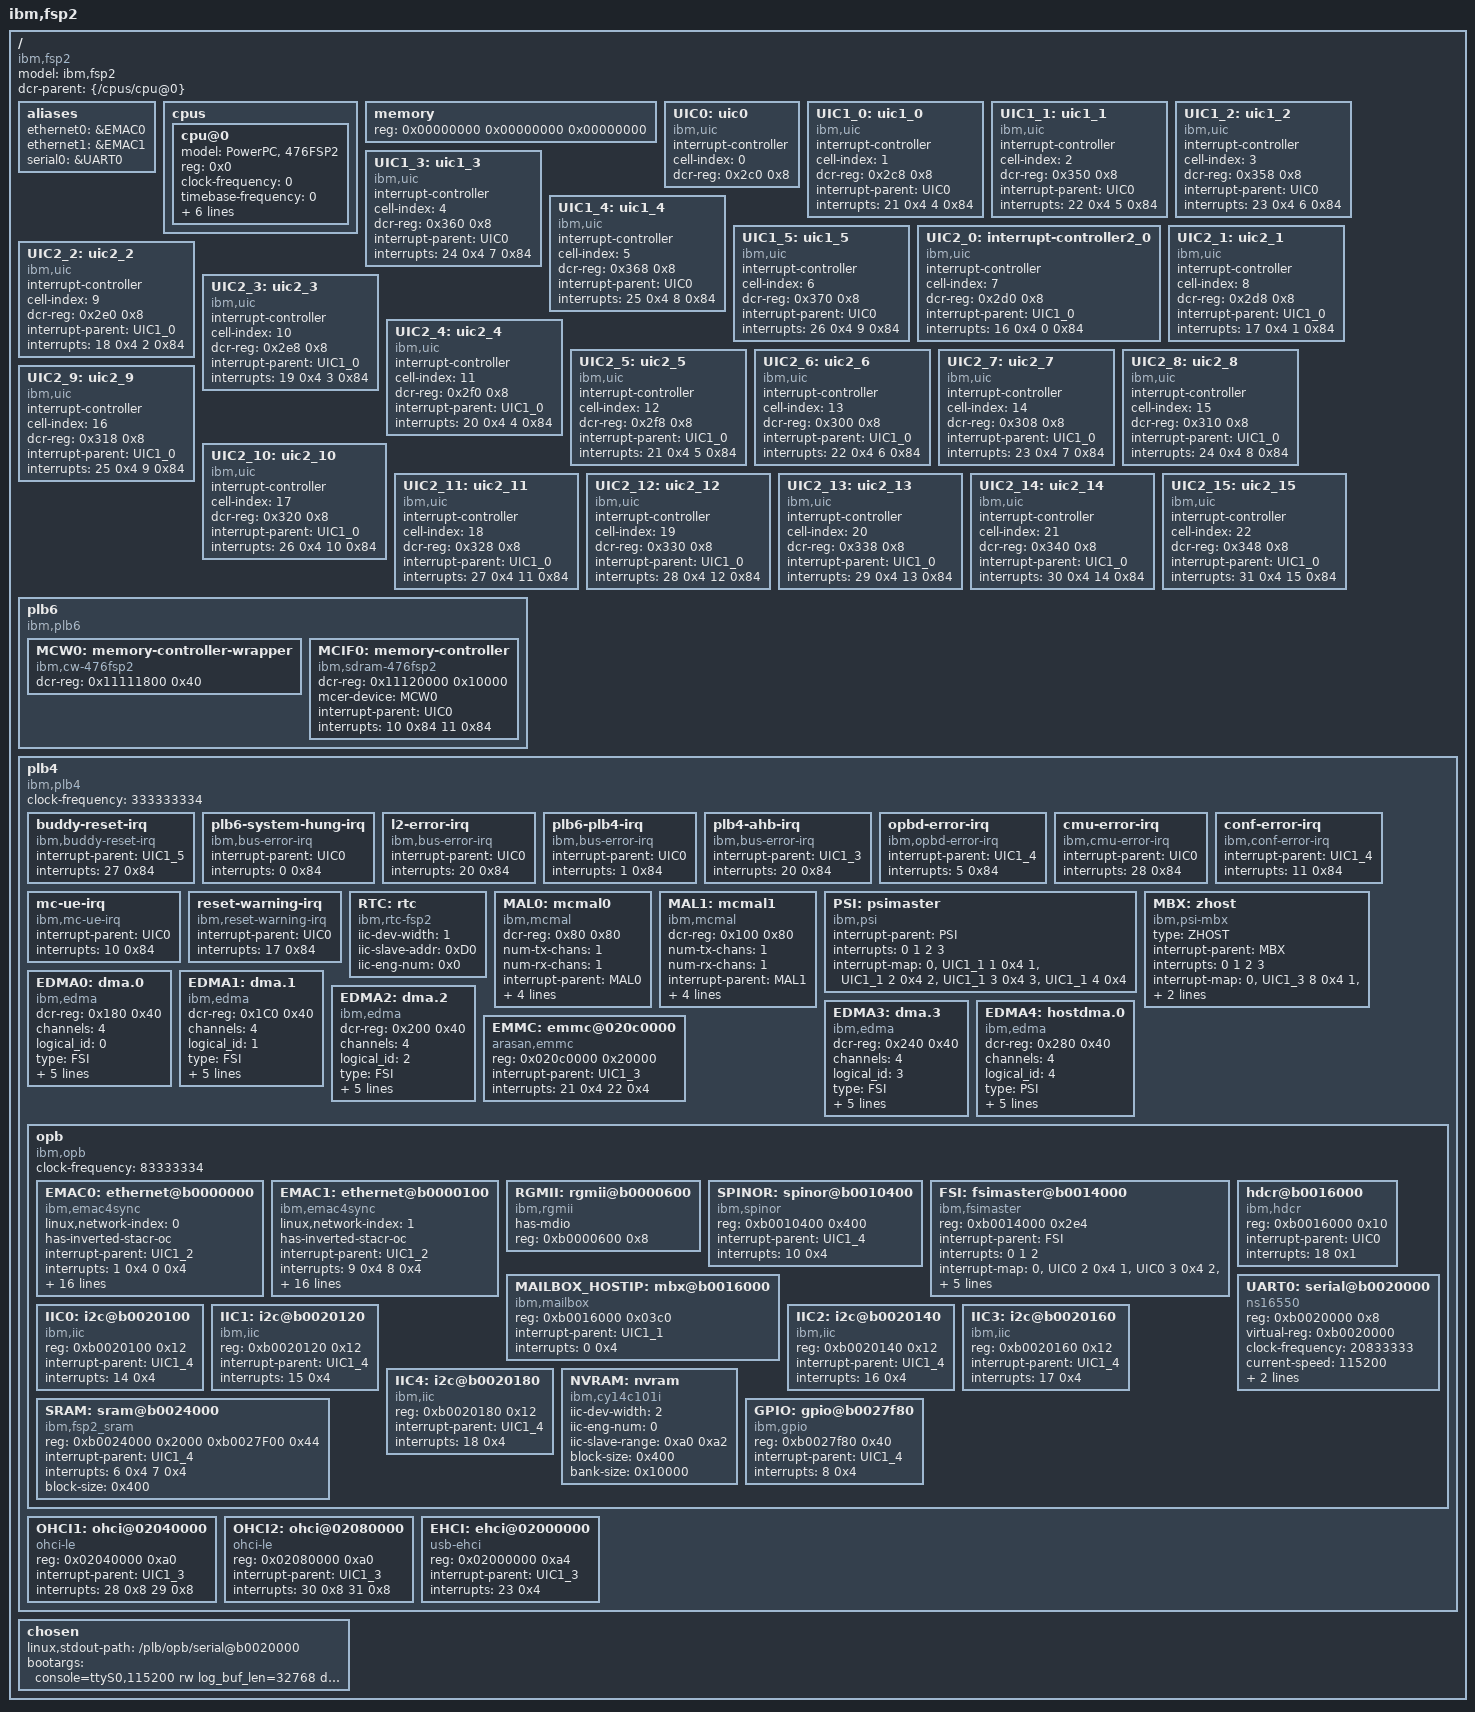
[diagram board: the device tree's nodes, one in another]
/*
 *   Copyright (c) International Business Machines Corp., 2010, 2012
 *
 *   This program is free software;  you can redistribute it and/or modify
 *   it under the terms of the GNU General Public License as published by
 *   the Free Software Foundation; either version 2 of the License, or
 *   (at your option) any later version.
 *
 *   This program is distributed in the hope that it will be useful,
 *   but WITHOUT ANY WARRANTY;  without even the implied warranty of
 *   MERCHANTABILITY or FITNESS FOR A PARTICULAR PURPOSE.  See
 *   the GNU General Public License for more details.
 *
 *   You should have received a copy of the GNU General Public License
 *   along with this program;  if not, write to the Free Software
 *   Foundation, Inc., 59 Temple Place, Suite 330, Boston, MA 02111-1307 USA
 */

/dts-v1/;

/ {
	#address-cells = <2>;
	#size-cells = <1>;
	model = "ibm,fsp2";
	compatible = "ibm,fsp2";
	dcr-parent = <&{/cpus/cpu@0}>;

	aliases {
		ethernet0 = &EMAC0;
		ethernet1 = &EMAC1;
		serial0 = &UART0;
	};

	cpus {
		#address-cells = <1>;
		#size-cells = <0>;

		cpu@0 {
			device_type = "cpu";
			model = "PowerPC, 476FSP2";
			reg = <0x0>;
			clock-frequency = <0>;    /* Filled in by cuboot */
			timebase-frequency = <0>; /* Filled in by cuboot */
			i-cache-line-size = <32>;
			d-cache-line-size = <32>;
			d-cache-size = <32768>;
			i-cache-size = <32768>;
			dcr-controller;
			dcr-access-method = "native";
		};
	};

	memory {
		device_type = "memory";
		reg = <0x00000000 0x00000000 0x00000000>; /* Filled in by
							     cuboot */
	};

	UIC0: uic0 {
		#address-cells = <0>;
		#size-cells = <0>;
		#interrupt-cells = <2>;
		compatible = "ibm,uic";
		interrupt-controller;
		cell-index = <0>;
		dcr-reg = <0x2c0 0x8>;
	};

	/* "interrupts" field is <bit level bit level>
	   first pair is non-critical, second is critical */
	UIC1_0: uic1_0 {
		#address-cells = <0>;
		#size-cells = <0>;
		#interrupt-cells = <2>;
		compatible = "ibm,uic";
		interrupt-controller;
		cell-index = <1>;
		dcr-reg = <0x2c8 0x8>;
		interrupt-parent = <&UIC0>;
		interrupts = <21 0x4 4 0x84>;
	};

	/* PSI and DMA */
	UIC1_1: uic1_1 {
		#address-cells = <0>;
		#size-cells = <0>;
		#interrupt-cells = <2>;
		compatible = "ibm,uic";
		interrupt-controller;
		cell-index = <2>;
		dcr-reg = <0x350 0x8>;
		interrupt-parent = <&UIC0>;
		interrupts = <22 0x4 5 0x84>;
	};

	/* Ethernet and USB */
	UIC1_2: uic1_2 {
		#address-cells = <0>;
		#size-cells = <0>;
		#interrupt-cells = <2>;
		compatible = "ibm,uic";
		interrupt-controller;
		cell-index = <3>;
		dcr-reg = <0x358 0x8>;
		interrupt-parent = <&UIC0>;
		interrupts = <23 0x4 6 0x84>;
	};

	/* PLB Errors */
	UIC1_3: uic1_3 {
		#address-cells = <0>;
		#size-cells = <0>;
		#interrupt-cells = <2>;
		compatible = "ibm,uic";
		interrupt-controller;
		cell-index = <4>;
		dcr-reg = <0x360 0x8>;
		interrupt-parent = <&UIC0>;
		interrupts = <24 0x4 7 0x84>;
	};

	UIC1_4: uic1_4 {
		#address-cells = <0>;
		#size-cells = <0>;
		#interrupt-cells = <2>;
		compatible = "ibm,uic";
		interrupt-controller;
		cell-index = <5>;
		dcr-reg = <0x368 0x8>;
		interrupt-parent = <&UIC0>;
		interrupts = <25 0x4 8 0x84>;
	};

	UIC1_5: uic1_5 {
		#address-cells = <0>;
		#size-cells = <0>;
		#interrupt-cells = <2>;
		compatible = "ibm,uic";
		interrupt-controller;
		cell-index = <6>;
		dcr-reg = <0x370 0x8>;
		interrupt-parent = <&UIC0>;
		interrupts = <26 0x4 9 0x84>;
	};

	/* 2nd level UICs for FSI */
	UIC2_0: interrupt-controller2_0 {
		#address-cells = <0>;
		#size-cells = <0>;
		#interrupt-cells = <2>;
		compatible = "ibm,uic";
		interrupt-controller;
		cell-index = <7>;
		dcr-reg = <0x2d0 0x8>;
		interrupt-parent = <&UIC1_0>;
		interrupts = <16 0x4 0 0x84>;
	};

	UIC2_1: uic2_1 {
		#address-cells = <0>;
		#size-cells = <0>;
		#interrupt-cells = <2>;
		compatible = "ibm,uic";
		interrupt-controller;
		cell-index = <8>;
		dcr-reg = <0x2d8 0x8>;
		interrupt-parent = <&UIC1_0>;
		interrupts = <17 0x4 1 0x84>;
	};

	UIC2_2: uic2_2 {
		#address-cells = <0>;
		#size-cells = <0>;
		#interrupt-cells = <2>;
		compatible = "ibm,uic";
		interrupt-controller;
		cell-index = <9>;
		dcr-reg = <0x2e0 0x8>;
		interrupt-parent = <&UIC1_0>;
		interrupts = <18 0x4 2 0x84>;
	};

	UIC2_3: uic2_3 {
		#address-cells = <0>;
		#size-cells = <0>;
		#interrupt-cells = <2>;
		compatible = "ibm,uic";
		interrupt-controller;
		cell-index = <10>;
		dcr-reg = <0x2e8 0x8>;
		interrupt-parent = <&UIC1_0>;
		interrupts = <19 0x4 3 0x84>;
	};

	UIC2_4: uic2_4 {
		#address-cells = <0>;
		#size-cells = <0>;
		#interrupt-cells = <2>;
		compatible = "ibm,uic";
		interrupt-controller;
		cell-index = <11>;
		dcr-reg = <0x2f0 0x8>;
		interrupt-parent = <&UIC1_0>;
		interrupts = <20 0x4 4 0x84>;
	};

	UIC2_5: uic2_5 {
		#address-cells = <0>;
		#size-cells = <0>;
		#interrupt-cells = <2>;
		compatible = "ibm,uic";
		interrupt-controller;
		cell-index = <12>;
		dcr-reg = <0x2f8 0x8>;
		interrupt-parent = <&UIC1_0>;
		interrupts = <21 0x4 5 0x84>;
	};

	UIC2_6: uic2_6 {
		#address-cells = <0>;
		#size-cells = <0>;
		#interrupt-cells = <2>;
		compatible = "ibm,uic";
		interrupt-controller;
		cell-index = <13>;
		dcr-reg = <0x300 0x8>;
		interrupt-parent = <&UIC1_0>;
		interrupts = <22 0x4 6 0x84>;
	};

	UIC2_7: uic2_7 {
		#address-cells = <0>;
		#size-cells = <0>;
		#interrupt-cells = <2>;
		compatible = "ibm,uic";
		interrupt-controller;
		cell-index = <14>;
		dcr-reg = <0x308 0x8>;
		interrupt-parent = <&UIC1_0>;
		interrupts = <23 0x4 7 0x84>;
	};

	UIC2_8: uic2_8 {
		#address-cells = <0>;
		#size-cells = <0>;
		#interrupt-cells = <2>;
		compatible = "ibm,uic";
		interrupt-controller;
		cell-index = <15>;
		dcr-reg = <0x310 0x8>;
		interrupt-parent = <&UIC1_0>;
		interrupts = <24 0x4 8 0x84>;
	};

	UIC2_9: uic2_9 {
		#address-cells = <0>;
		#size-cells = <0>;
		#interrupt-cells = <2>;
		compatible = "ibm,uic";
		interrupt-controller;
		cell-index = <16>;
		dcr-reg = <0x318 0x8>;
		interrupt-parent = <&UIC1_0>;
		interrupts = <25 0x4 9 0x84>;
	};

	UIC2_10: uic2_10 {
		#address-cells = <0>;
		#size-cells = <0>;
		#interrupt-cells = <2>;
		compatible = "ibm,uic";
		interrupt-controller;
		cell-index = <17>;
		dcr-reg = <0x320 0x8>;
		interrupt-parent = <&UIC1_0>;
		interrupts = <26 0x4 10 0x84>;
	};

	UIC2_11: uic2_11 {
		#address-cells = <0>;
		#size-cells = <0>;
		#interrupt-cells = <2>;
		compatible = "ibm,uic";
		interrupt-controller;
		cell-index = <18>;
		dcr-reg = <0x328 0x8>;
		interrupt-parent = <&UIC1_0>;
		interrupts = <27 0x4 11 0x84>;
	};

	UIC2_12: uic2_12 {
		#address-cells = <0>;
		#size-cells = <0>;
		#interrupt-cells = <2>;
		compatible = "ibm,uic";
		interrupt-controller;
		cell-index = <19>;
		dcr-reg = <0x330 0x8>;
		interrupt-parent = <&UIC1_0>;
		interrupts = <28 0x4 12 0x84>;
	};

	UIC2_13: uic2_13 {
		#address-cells = <0>;
		#size-cells = <0>;
		#interrupt-cells = <2>;
		compatible = "ibm,uic";
		interrupt-controller;
		cell-index = <20>;
		dcr-reg = <0x338 0x8>;
		interrupt-parent = <&UIC1_0>;
		interrupts = <29 0x4 13 0x84>;
	};

	UIC2_14: uic2_14 {
		#address-cells = <0>;
		#size-cells = <0>;
		#interrupt-cells = <2>;
		compatible = "ibm,uic";
		interrupt-controller;
		cell-index = <21>;
		dcr-reg = <0x340 0x8>;
		interrupt-parent = <&UIC1_0>;
		interrupts = <30 0x4 14 0x84>;
	};

	UIC2_15: uic2_15 {
		#address-cells = <0>;
		#size-cells = <0>;
		#interrupt-cells = <2>;
		compatible = "ibm,uic";
		interrupt-controller;
		cell-index = <22>;
		dcr-reg = <0x348 0x8>;
		interrupt-parent = <&UIC1_0>;
		interrupts = <31 0x4 15 0x84>;
	};

	plb6 {
		compatible = "ibm,plb6";
		#address-cells = <2>;
		#size-cells = <1>;
		ranges;

		MCW0: memory-controller-wrapper {
			compatible = "ibm,cw-476fsp2";
			dcr-reg = <0x11111800 0x40>;
		};

		MCIF0: memory-controller {
			compatible = "ibm,sdram-476fsp2", "ibm,sdram-4xx-ddr3";
			dcr-reg = <0x11120000 0x10000>;
			mcer-device = <&MCW0>;
			interrupt-parent = <&UIC0>;
			interrupts = <10 0x84   /* ECC UE */
			              11 0x84>; /* ECC CE */
		};
	};

	plb4 {
		compatible = "ibm,plb4";
		#address-cells = <1>;
		#size-cells = <1>;
		ranges = <0x00000000 0x00000010 0x00000000 0x80000000
			  0x80000000 0x00000010 0x80000000 0x80000000>;
		clock-frequency = <333333334>;

		buddy-reset-irq {
			compatible = "ibm,buddy-reset-irq";

			#interrupt-cells = <2>;
			interrupt-parent = <&UIC1_5>;
			interrupts = <27 0x84>;
		};

		plb6-system-hung-irq {
			compatible = "ibm,bus-error-irq";

			#interrupt-cells = <2>;
			interrupt-parent = <&UIC0>;
			interrupts = <0 0x84>;
		};

		l2-error-irq {
			compatible = "ibm,bus-error-irq";

			#interrupt-cells = <2>;
			interrupt-parent = <&UIC0>;
			interrupts = <20 0x84>;
		};

		plb6-plb4-irq {
			compatible = "ibm,bus-error-irq";

			#interrupt-cells = <2>;
			interrupt-parent = <&UIC0>;
			interrupts = <1 0x84>;
		};

		plb4-ahb-irq {
			compatible = "ibm,bus-error-irq";

			#interrupt-cells = <2>;
			interrupt-parent = <&UIC1_3>;
			interrupts = <20 0x84>;
		};

		opbd-error-irq {
			compatible = "ibm,opbd-error-irq";

			#interrupt-cells = <2>;
			interrupt-parent = <&UIC1_4>;
			interrupts = <5 0x84>;
		};

		cmu-error-irq {
			compatible = "ibm,cmu-error-irq";

			#interrupt-cells = <2>;
			interrupt-parent = <&UIC0>;
			interrupts = <28 0x84>;
		};

		conf-error-irq {
			compatible = "ibm,conf-error-irq";

			#interrupt-cells = <2>;
			interrupt-parent = <&UIC1_4>;
			interrupts = <11 0x84>;
		};

		mc-ue-irq {
			compatible = "ibm,mc-ue-irq";

			#interrupt-cells = <2>;
			interrupt-parent = <&UIC0>;
			interrupts = <10 0x84>;
		};

		reset-warning-irq {
			compatible = "ibm,reset-warning-irq";

			#interrupt-cells = <2>;
			interrupt-parent = <&UIC0>;
			interrupts = <17 0x84>;
		};


               RTC: rtc {
                       device_type = "rtc";
                       compatible = "ibm,rtc-fsp2";
                       iic-dev-width = <1>;
                       iic-slave-addr = <0xD0>;
                       iic-eng-num = <0x0>;
               };

		MAL0: mcmal0 {
			#interrupt-cells = <1>;
			#address-cells = <0>;
			#size-cells = <0>;
			compatible = "ibm,mcmal";
			dcr-reg = <0x80 0x80>;
			num-tx-chans = <1>;
			num-rx-chans = <1>;
			interrupt-parent = <&MAL0>;
			interrupts = <0 1 2 3 4>;
			/* index interrupt-parent interrupt# type */
			interrupt-map = </*TXEOB*/ 0 &UIC1_2 4 0x4
					 /*RXEOB*/ 1 &UIC1_2 3 0x4
					 /*SERR*/  2 &UIC1_2 7 0x4
					 /*TXDE*/  3 &UIC1_2 6 0x4
					 /*RXDE*/  4 &UIC1_2 5 0x4>;
		};

		MAL1: mcmal1 {
			#interrupt-cells = <1>;
			#address-cells = <0>;
			#size-cells = <0>;
			compatible = "ibm,mcmal";
			dcr-reg = <0x100 0x80>;
			num-tx-chans = <1>;
			num-rx-chans = <1>;
			interrupt-parent = <&MAL1>;
			interrupts = <0 1 2 3 4>;
			/* index interrupt-parent interrupt# type */
			interrupt-map = </*TXEOB*/ 0 &UIC1_2 12 0x4
					 /*RXEOB*/ 1 &UIC1_2 11 0x4
					 /*SERR*/  2 &UIC1_2 15 0x4
					 /*TXDE*/  3 &UIC1_2 14 0x4
					 /*RXDE*/  4 &UIC1_2 13 0x4>;
		};

                PSI: psimaster {
			#interrupt-cells = <1>;
			#address-cells = <0>;
			#size-cells = <0>;
			compatible = "ibm,psi";

                        interrupt-parent = <&PSI>;
                        interrupts = <0 1 2 3>;
                        /* index interrupt-parent interrupt# type */
                        interrupt-map = </*Link 0*/ 0 &UIC1_1 1 0x4
					 /*Link 1*/ 1 &UIC1_1 2 0x4
					 /*Link 2*/ 2 &UIC1_1 3 0x4
					 /*Link 3*/ 3 &UIC1_1 4 0x4>;
		};

                MBX: zhost {
                        #interrupt-cells = <1>;
                        #address-cells = <0>;
                        #size-cells = <0>;
                        compatible = "ibm,psi-mbx";
                        type = "ZHOST";
                        interrupt-parent = <&MBX>;
                        interrupts = <0 1 2 3>; 
                        /* index interrupt-parent interrupt# type */
                        interrupt-map = </*Link 0*/ 0 &UIC1_3 8 0x4 
                                         /*Link 1*/ 1 &UIC1_3 9 0x4 
                                         /*Link 2*/ 2 &UIC1_3 10 0x4 
                                         /*Link 3*/ 3 &UIC1_3 11 0x4>;
                };  

		EDMA0: dma.0 {
			#interrupt-cells = <1>;
			#address-cells = <0>;
			#size-cells = <0>;
			compatible = "ibm,edma";
			dcr-reg = <0x180 0x40>;
			channels = <4>;
			logical_id = <0>;
			type = "FSI";
			interrupt-parent = <&EDMA0>;
			interrupts = <0 1 2 3>;
			/* index interrupt-parent interrupt# type */
			interrupt-map = < /* chnl_0 */ 0 &UIC1_1  28 0x4
					  /* chnl_1 */ 1 &UIC1_1  29 0x4
					  /* chnl_2 */ 2 &UIC1_1  30 0x4
					  /* chnl_3 */ 3 &UIC1_1  31 0x4>;
		};

		EDMA1: dma.1 {
			#interrupt-cells = <1>;
			#address-cells = <0>;
			#size-cells = <0>;
			compatible = "ibm,edma";
			dcr-reg = <0x1C0 0x40>;
			channels = <4>;
			logical_id = <1>;
			type = "FSI";
			interrupt-parent = <&EDMA1>;
			interrupts = <0 1 2 3>;
			/* index interrupt-parent interrupt# type */
			interrupt-map = < /* chnl_0 */ 0 &UIC1_1  24 0x4
					  /* chnl_1 */ 1 &UIC1_1  25 0x4
					  /* chnl_2 */ 2 &UIC1_1  26 0x4
					  /* chnl_3 */ 3 &UIC1_1  27 0x4>;
		};

		EDMA2: dma.2 {
			#interrupt-cells = <1>;
			#address-cells = <0>;
			#size-cells = <0>;
			compatible = "ibm,edma";
			dcr-reg = <0x200 0x40>;
			channels = <4>;
			logical_id = <2>;
			type = "FSI";
			interrupt-parent = <&EDMA2>;
			interrupts = <0 1 2 3>;
			/* index interrupt-parent interrupt# type */
			interrupt-map = < /* chnl_0 */ 0 &UIC1_1  20 0x4
					  /* chnl_1 */ 1 &UIC1_1  21 0x4
					  /* chnl_2 */ 2 &UIC1_1  22 0x4
					  /* chnl_3 */ 3 &UIC1_1  23 0x4>;
		};

		EDMA3: dma.3 {
			#interrupt-cells = <1>;
			#address-cells = <0>;
			#size-cells = <0>;
			compatible = "ibm,edma";
			dcr-reg = <0x240 0x40>;
			channels = <4>;
			logical_id = <3>;
			type = "FSI";
			/* type = <DMA_FSI>; */
			interrupt-parent = <&EDMA3>;
			interrupts = <0 1 2 3>;
			/* index interrupt-parent interrupt# type */
			interrupt-map = < /* chnl_0 */ 0 &UIC1_1  16 0x4
					  /* chnl_1 */ 1 &UIC1_1  17 0x4
					  /* chnl_2 */ 2 &UIC1_1  18 0x4
					  /* chnl_3 */ 3 &UIC1_1  19 0x4>;
		};

		EDMA4: hostdma.0 {
			#interrupt-cells = <1>;
			#address-cells = <0>;
			#size-cells = <0>;
			compatible = "ibm,edma", "ibm,hostdma";
			dcr-reg = <0x280 0x40>;
			channels = <4>;
			logical_id = <4>;
			type = "PSI";
			/* type = <DMA_PSI>; */
			interrupt-parent = <&EDMA4>;
			interrupts = <0 1 2 3 4>;
			/* index interrupt-parent interrupt# type */
			interrupt-map = < /* chnl_0 */  0 &UIC1_1  12 0x4
					  /* chnl_1 */  1 &UIC1_1  13 0x4
					  /* chnl_2 */  2 &UIC1_1  14 0x4
					  /* chnl_3 */  3 &UIC1_1  15 0x4
					  /* HDCR_RW */ 4 &UIC0    18 0x1>;
		};

		EMMC: emmc@020c0000 {
			compatible = "arasan,emmc";
			reg = <0x020c0000 0x20000>;
			interrupt-parent = <&UIC1_3>;
			interrupts = <21 0x4	/* INT  */
				      22 0x4>;  /* WKUP */

		};

		opb {
			compatible = "ibm,opb";
			#address-cells = <1>;
			#size-cells = <1>;
			ranges; // pass-thru to parent bus
			clock-frequency = <83333334>;

			EMAC0: ethernet@b0000000 {
				linux,network-index = <0>;
				device_type = "network";
				compatible = "ibm,emac4sync";
				has-inverted-stacr-oc;
				interrupt-parent = <&UIC1_2>;
				interrupts = <1 0x4 0 0x4>;
				reg = <0xb0000000 0x100>;
				local-mac-address = [000000000000]; /* Filled in by
							       cuboot */
				mal-device = <&MAL0>;
				mal-tx-channel = <0>;
				mal-rx-channel = <0>;
				cell-index = <0>;
				max-frame-size = <1500>;
				rx-fifo-size = <4096>;
				tx-fifo-size = <4096>;
				rx-fifo-size-gige = <16384>;
				tx-fifo-size-gige = <8192>;
				phy-address = <1>;
				phy-mode = "rgmii";
				phy-map = <00000003>;
				rgmii-device = <&RGMII>;
				rgmii-channel = <0>;
			};

			EMAC1: ethernet@b0000100 {
				linux,network-index = <1>;
				device_type = "network";
				compatible = "ibm,emac4sync";
				has-inverted-stacr-oc;
				interrupt-parent = <&UIC1_2>;
				interrupts = <9 0x4 8 0x4>;
				reg = <0xb0000100 0x100>;
				local-mac-address = [000000000000]; /* Filled in by
							       cuboot */
				mal-device = <&MAL1>;
				mal-tx-channel = <0>;
				mal-rx-channel = <0>;
				cell-index = <1>;
				max-frame-size = <1500>;
				rx-fifo-size = <4096>;
				tx-fifo-size = <4096>;
				rx-fifo-size-gige = <16384>;
				tx-fifo-size-gige = <8192>;
				phy-address = <2>;
				phy-mode = "rgmii";
				phy-map = <00000003>;
				rgmii-device = <&RGMII>;
				rgmii-channel = <1>;
			};

			//TODO: MIB?

			RGMII: rgmii@b0000600 {
				compatible = "ibm,rgmii";
				has-mdio;
				reg = <0xb0000600 0x8>;
			};

			SPINOR: spinor@b0010400 {
				compatible ="ibm,spinor";
				reg = <0xb0010400 0x400>;
				interrupt-parent = <&UIC1_4>;
				interrupts = <10 0x4>;
			};

			FSI: fsimaster@b0014000 {
				compatible = "ibm,fsimaster";
				#interrupt-cells = <1>;
				#address-cells = <0>;
				reg = <0xb0014000 0x2e4>;
				interrupt-parent = <&FSI>;
				interrupts = <0 1 2>;
				interrupt-map =</*Port Err*/	0 &UIC0 2  0x4
						/*Master Err*/	1 &UIC0 3  0x4
						/*Plug Detect*/	2 &UIC0 27 0x4>;
				cfam-uics = <&UIC2_0 &UIC2_1 &UIC2_2 &UIC2_3
					     &UIC2_4 &UIC2_5 &UIC2_6 &UIC2_7
					     &UIC2_8 &UIC2_9 &UIC2_10 &UIC2_11
					     &UIC2_12 &UIC2_13 &UIC2_14
					     &UIC2_15>;
			};

			MAILBOX_HOSTIP: mbx@b0016000 {
				compatible = "ibm,mailbox";

				reg = <0xb0016000 0x03c0>;

				interrupt-parent = <&UIC1_1>;
				interrupts = <0 0x4>;
			};

			hdcr@b0016000 {
				compatible = "ibm,hdcr";

				reg = <0xb0016000 0x10>;

				interrupt-parent = <&UIC0>;
				interrupts = <18 0x1>;
			};

			UART0: serial@b0020000 {
				device_type = "serial";
				compatible = "ns16550";
				reg = <0xb0020000 0x8>;
				virtual-reg = <0xb0020000>;
				clock-frequency = <20833333>;
				current-speed = <115200>;
				interrupt-parent = <&UIC0>;
				interrupts = <31 0x4>;
			};

			IIC0: i2c@b0020100 {
				compatible = "ibm,iic";
				reg = <0xb0020100 0x12>;
				interrupt-parent = <&UIC1_4>;
				interrupts = <14 0x4>;
				/* TODO: add bus connections here?  see canyonlands.dts
				 * IIC0 for an example. */
			};

			IIC1: i2c@b0020120 {
				compatible = "ibm,iic";
				reg = <0xb0020120 0x12>;
				interrupt-parent = <&UIC1_4>;
				interrupts = <15 0x4>;
			};

			IIC2: i2c@b0020140 {
				compatible = "ibm,iic";
				reg = <0xb0020140 0x12>;
				interrupt-parent = <&UIC1_4>;
				interrupts = <16 0x4>;
			};

			IIC3: i2c@b0020160 {
				compatible = "ibm,iic";
				reg = <0xb0020160 0x12>;
				interrupt-parent = <&UIC1_4>;
				interrupts = <17 0x4>;
			};

			IIC4: i2c@b0020180 {
				compatible = "ibm,iic";
				reg = <0xb0020180 0x12>;
				interrupt-parent = <&UIC1_4>;
				interrupts = <18 0x4>;
			};

			SRAM: sram@b0024000 {
				compatible = "ibm,fsp2_sram";
				reg = <0xb0024000 0x2000 0xb0027F00 0x44>;
				interrupt-parent = <&UIC1_4>;
				interrupts = <6 0x4 7 0x4>;
				block-size = <0x400>;
			};

			NVRAM: nvram {
				compatible = "ibm,cy14c101i";
				iic-dev-width = <2>;
				iic-eng-num = <0>;
				iic-slave-range = <0xa0 0xa2>;
				block-size = <0x400>;
				bank-size = <0x10000>;
			};

			GPIO: gpio@b0027f80 {
				compatible = "ibm,gpio";
				reg = <0xb0027f80 0x40>;
				interrupt-parent = <&UIC1_4>;
				interrupts = <8 0x4>;
			};
                };

		//TODO: USB, PCIe, P Mailbox
		OHCI1: ohci@02040000 {
			compatible = "ohci-le";
			reg = <0x02040000 0xa0>;
			interrupt-parent = <&UIC1_3>;
			interrupts = <28 0x8 29 0x8>;
		};

		OHCI2: ohci@02080000 {
			compatible = "ohci-le";
			reg = <0x02080000 0xa0>;
			interrupt-parent = <&UIC1_3>;
			interrupts = <30 0x8 31 0x8>;
		};

		EHCI: ehci@02000000 {
			compatible = "usb-ehci";
			reg = <0x02000000 0xa4>;
			interrupt-parent = <&UIC1_3>;
			interrupts = <23 0x4>;
		};

	};

	chosen {
		linux,stdout-path = "/plb/opb/serial@b0020000";
		bootargs = "console=ttyS0,115200 rw log_buf_len=32768 debug";
	};
};
